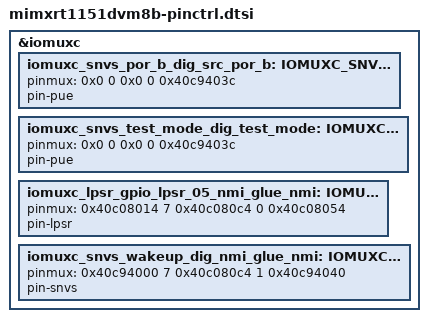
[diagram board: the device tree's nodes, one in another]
/*
 * Copyright 2026, NXP
 * SPDX-License-Identifier: Apache-2.0
 *
 * Note: File generated by gen_soc_headers.py
 * from configuration data for MIMXRT1151DVM8B
 */

/*
 * Delta-deduplicated by dedup_pinctrl.py:
 * based on mimxrt1176avm8a-pinctrl.dtsi with this part's differences applied
 * below (171 removed, 2 changed,
 * 2 added). Regenerate with dedup_pinctrl.py;
 * do not edit by hand.
 * target-hash: d0dcf505715381c8
 */

#include "mimxrt1176avm8a-pinctrl.dtsi"

/delete-node/ &iomuxc_gpio_ad_00_sim1_trxd;
/delete-node/ &iomuxc_gpio_ad_01_sim1_clk;
/delete-node/ &iomuxc_gpio_ad_02_sim1_rst_b;
/delete-node/ &iomuxc_gpio_ad_03_sim1_sven;
/delete-node/ &iomuxc_gpio_ad_04_sim1_pd;
/delete-node/ &iomuxc_gpio_ad_05_sim1_power_fail;
/delete-node/ &iomuxc_gpio_ad_06_enet_1588_event1_in;
/delete-node/ &iomuxc_gpio_ad_06_sim2_trxd;
/delete-node/ &iomuxc_gpio_ad_06_video_mux_csi_data15;
/delete-node/ &iomuxc_gpio_ad_07_enet_1588_event1_out;
/delete-node/ &iomuxc_gpio_ad_07_sim2_clk;
/delete-node/ &iomuxc_gpio_ad_07_video_mux_csi_data14;
/delete-node/ &iomuxc_gpio_ad_08_enet_1588_event2_in;
/delete-node/ &iomuxc_gpio_ad_08_sim2_rst_b;
/delete-node/ &iomuxc_gpio_ad_08_video_mux_csi_data13;
/delete-node/ &iomuxc_gpio_ad_09_enet_1588_event2_out;
/delete-node/ &iomuxc_gpio_ad_09_sim2_sven;
/delete-node/ &iomuxc_gpio_ad_09_video_mux_csi_data12;
/delete-node/ &iomuxc_gpio_ad_10_enet_1588_event3_in;
/delete-node/ &iomuxc_gpio_ad_10_sim2_pd;
/delete-node/ &iomuxc_gpio_ad_10_video_mux_csi_data11;
/delete-node/ &iomuxc_gpio_ad_11_enet_1588_event3_out;
/delete-node/ &iomuxc_gpio_ad_11_sim2_power_fail;
/delete-node/ &iomuxc_gpio_ad_11_video_mux_csi_data10;
/delete-node/ &iomuxc_gpio_ad_12_enet_tdata03;
/delete-node/ &iomuxc_gpio_ad_12_video_mux_csi_pixclk;
/delete-node/ &iomuxc_gpio_ad_13_enet_tdata02;
/delete-node/ &iomuxc_gpio_ad_13_video_mux_csi_mclk;
/delete-node/ &iomuxc_gpio_ad_14_enet_rx_clk;
/delete-node/ &iomuxc_gpio_ad_14_video_mux_csi_vsync;
/delete-node/ &iomuxc_gpio_ad_15_enet_tx_er;
/delete-node/ &iomuxc_gpio_ad_15_lpuart10_tx;
/delete-node/ &iomuxc_gpio_ad_15_video_mux_csi_hsync;
/delete-node/ &iomuxc_gpio_ad_16_enet_rdata03;
/delete-node/ &iomuxc_gpio_ad_16_lpuart10_rx;
/delete-node/ &iomuxc_gpio_ad_16_video_mux_csi_data09;
/delete-node/ &iomuxc_gpio_ad_17_enet_rdata02;
/delete-node/ &iomuxc_gpio_ad_17_video_mux_csi_data08;
/delete-node/ &iomuxc_gpio_ad_18_enet_crs;
/delete-node/ &iomuxc_gpio_ad_18_video_mux_csi_data07;
/delete-node/ &iomuxc_gpio_ad_19_enet_col;
/delete-node/ &iomuxc_gpio_ad_19_video_mux_csi_data06;
/delete-node/ &iomuxc_gpio_ad_20_video_mux_csi_data05;
/delete-node/ &iomuxc_gpio_ad_21_video_mux_csi_data04;
/delete-node/ &iomuxc_gpio_ad_22_video_mux_csi_data03;
/delete-node/ &iomuxc_gpio_ad_23_video_mux_csi_data02;
/delete-node/ &iomuxc_gpio_ad_24_enet_rx_en;
/delete-node/ &iomuxc_gpio_ad_24_video_mux_csi_data00;
/delete-node/ &iomuxc_gpio_ad_25_enet_rx_er;
/delete-node/ &iomuxc_gpio_ad_25_video_mux_csi_data01;
/delete-node/ &iomuxc_gpio_ad_26_enet_rdata00;
/delete-node/ &iomuxc_gpio_ad_27_enet_rdata01;
/delete-node/ &iomuxc_gpio_ad_28_enet_tx_en;
/delete-node/ &iomuxc_gpio_ad_29_enet_ref_clk;
/delete-node/ &iomuxc_gpio_ad_29_enet_tx_clk;
/delete-node/ &iomuxc_gpio_ad_30_enet_tdata00;
/delete-node/ &iomuxc_gpio_ad_31_enet_tdata01;
/delete-node/ &iomuxc_gpio_ad_32_enet_mdc;
/delete-node/ &iomuxc_gpio_ad_32_lpuart10_tx;
/delete-node/ &iomuxc_gpio_ad_33_enet_mdio;
/delete-node/ &iomuxc_gpio_ad_33_lpuart10_rx;
/delete-node/ &iomuxc_gpio_ad_34_enet_1588_event0_in;
/delete-node/ &iomuxc_gpio_ad_34_lpuart10_cts_b;
/delete-node/ &iomuxc_gpio_ad_35_enet_1588_event0_out;
/delete-node/ &iomuxc_gpio_ad_35_lpuart10_rts_b;
/delete-node/ &iomuxc_gpio_disp_b1_00_video_mux_lcdif_clk;
/delete-node/ &iomuxc_gpio_disp_b1_01_video_mux_lcdif_enable;
/delete-node/ &iomuxc_gpio_disp_b1_02_video_mux_lcdif_hsync;
/delete-node/ &iomuxc_gpio_disp_b1_03_video_mux_lcdif_vsync;
/delete-node/ &iomuxc_gpio_disp_b1_04_lpuart4_rx;
/delete-node/ &iomuxc_gpio_disp_b1_04_video_mux_lcdif_data00;
/delete-node/ &iomuxc_gpio_disp_b1_05_lpuart4_cts_b;
/delete-node/ &iomuxc_gpio_disp_b1_05_video_mux_lcdif_data01;
/delete-node/ &iomuxc_gpio_disp_b1_06_lpuart4_tx;
/delete-node/ &iomuxc_gpio_disp_b1_06_video_mux_lcdif_data02;
/delete-node/ &iomuxc_gpio_disp_b1_07_lpuart4_rts_b;
/delete-node/ &iomuxc_gpio_disp_b1_07_video_mux_lcdif_data03;
/delete-node/ &iomuxc_gpio_disp_b1_08_video_mux_lcdif_data04;
/delete-node/ &iomuxc_gpio_disp_b1_09_video_mux_lcdif_data05;
/delete-node/ &iomuxc_gpio_disp_b1_10_video_mux_lcdif_data06;
/delete-node/ &iomuxc_gpio_disp_b1_11_video_mux_lcdif_data07;
/delete-node/ &iomuxc_gpio_disp_b2_00_video_mux_lcdif_data08;
/delete-node/ &iomuxc_gpio_disp_b2_01_video_mux_lcdif_data09;
/delete-node/ &iomuxc_gpio_disp_b2_02_enet_tdata00;
/delete-node/ &iomuxc_gpio_disp_b2_02_video_mux_lcdif_data10;
/delete-node/ &iomuxc_gpio_disp_b2_03_enet_tdata01;
/delete-node/ &iomuxc_gpio_disp_b2_03_video_mux_lcdif_data11;
/delete-node/ &iomuxc_gpio_disp_b2_04_enet_tx_en;
/delete-node/ &iomuxc_gpio_disp_b2_04_video_mux_lcdif_data12;
/delete-node/ &iomuxc_gpio_disp_b2_05_enet_ref_clk;
/delete-node/ &iomuxc_gpio_disp_b2_05_enet_tx_clk;
/delete-node/ &iomuxc_gpio_disp_b2_05_video_mux_lcdif_data13;
/delete-node/ &iomuxc_gpio_disp_b2_06_enet_rdata00;
/delete-node/ &iomuxc_gpio_disp_b2_06_video_mux_lcdif_data14;
/delete-node/ &iomuxc_gpio_disp_b2_07_enet_rdata01;
/delete-node/ &iomuxc_gpio_disp_b2_07_video_mux_lcdif_data15;
/delete-node/ &iomuxc_gpio_disp_b2_08_enet_rx_en;
/delete-node/ &iomuxc_gpio_disp_b2_08_video_mux_lcdif_data16;
/delete-node/ &iomuxc_gpio_disp_b2_09_enet_rx_er;
/delete-node/ &iomuxc_gpio_disp_b2_09_video_mux_lcdif_data17;
/delete-node/ &iomuxc_gpio_disp_b2_10_sim2_trxd;
/delete-node/ &iomuxc_gpio_disp_b2_10_video_mux_lcdif_data18;
/delete-node/ &iomuxc_gpio_disp_b2_11_sim2_clk;
/delete-node/ &iomuxc_gpio_disp_b2_11_video_mux_lcdif_data19;
/delete-node/ &iomuxc_gpio_disp_b2_12_sim2_rst_b;
/delete-node/ &iomuxc_gpio_disp_b2_12_video_mux_lcdif_data20;
/delete-node/ &iomuxc_gpio_disp_b2_13_enet_ref_clk;
/delete-node/ &iomuxc_gpio_disp_b2_13_sim2_sven;
/delete-node/ &iomuxc_gpio_disp_b2_13_video_mux_lcdif_data21;
/delete-node/ &iomuxc_gpio_disp_b2_14_sim2_pd;
/delete-node/ &iomuxc_gpio_disp_b2_14_video_mux_lcdif_data22;
/delete-node/ &iomuxc_gpio_disp_b2_15_sim2_power_fail;
/delete-node/ &iomuxc_gpio_disp_b2_15_video_mux_lcdif_data23;
/delete-node/ &iomuxc_gpio_emc_b2_02_video_mux_csi_data23;
/delete-node/ &iomuxc_gpio_emc_b2_03_video_mux_csi_data22;
/delete-node/ &iomuxc_gpio_emc_b2_04_video_mux_csi_data21;
/delete-node/ &iomuxc_gpio_emc_b2_05_video_mux_csi_data20;
/delete-node/ &iomuxc_gpio_emc_b2_06_video_mux_csi_data19;
/delete-node/ &iomuxc_gpio_emc_b2_07_video_mux_csi_data18;
/delete-node/ &iomuxc_gpio_emc_b2_08_video_mux_csi_data17;
/delete-node/ &iomuxc_gpio_emc_b2_09_video_mux_csi_data16;
/delete-node/ &iomuxc_gpio_emc_b2_10_video_mux_csi_field;
/delete-node/ &iomuxc_gpio_emc_b2_11_sim1_trxd;
/delete-node/ &iomuxc_gpio_emc_b2_12_sim1_clk;
/delete-node/ &iomuxc_gpio_emc_b2_13_sim1_rst_b;
/delete-node/ &iomuxc_gpio_emc_b2_14_sim1_sven;
/delete-node/ &iomuxc_gpio_emc_b2_15_sim1_pd;
/delete-node/ &iomuxc_gpio_emc_b2_16_sim1_power_fail;
/delete-node/ &iomuxc_gpio_emc_b2_19_enet_mdc;
/delete-node/ &iomuxc_gpio_emc_b2_20_enet_mdio;
/delete-node/ &iomuxc_gpio_sd_b2_07_enet_tx_er;
/delete-node/ &iomuxc_lpsr_gpio_lpsr_00_can3_tx;
/delete-node/ &iomuxc_lpsr_gpio_lpsr_00_sai4_mclk;
/delete-node/ &iomuxc_lpsr_gpio_lpsr_01_can3_rx;
/delete-node/ &iomuxc_lpsr_gpio_lpsr_02_sai4_tx_data;
/delete-node/ &iomuxc_lpsr_gpio_lpsr_03_sai4_tx_sync;
/delete-node/ &iomuxc_lpsr_gpio_lpsr_04_lpi2c5_sda;
/delete-node/ &iomuxc_lpsr_gpio_lpsr_04_lpuart11_tx;
/delete-node/ &iomuxc_lpsr_gpio_lpsr_04_sai4_tx_bclk;
/delete-node/ &iomuxc_lpsr_gpio_lpsr_05_lpi2c5_scl;
/delete-node/ &iomuxc_lpsr_gpio_lpsr_05_lpuart11_rx;
/delete-node/ &iomuxc_lpsr_gpio_lpsr_05_sai4_mclk;
/delete-node/ &iomuxc_lpsr_gpio_lpsr_06_can3_tx;
/delete-node/ &iomuxc_lpsr_gpio_lpsr_06_lpspi6_pcs3;
/delete-node/ &iomuxc_lpsr_gpio_lpsr_06_sai4_rx_data;
/delete-node/ &iomuxc_lpsr_gpio_lpsr_07_can3_rx;
/delete-node/ &iomuxc_lpsr_gpio_lpsr_07_lpspi6_pcs2;
/delete-node/ &iomuxc_lpsr_gpio_lpsr_07_sai4_rx_bclk;
/delete-node/ &iomuxc_lpsr_gpio_lpsr_08_can3_tx;
/delete-node/ &iomuxc_lpsr_gpio_lpsr_08_lpi2c5_sda;
/delete-node/ &iomuxc_lpsr_gpio_lpsr_08_lpspi6_pcs1;
/delete-node/ &iomuxc_lpsr_gpio_lpsr_08_lpuart11_tx;
/delete-node/ &iomuxc_lpsr_gpio_lpsr_08_sai4_rx_sync;
/delete-node/ &iomuxc_lpsr_gpio_lpsr_09_can3_rx;
/delete-node/ &iomuxc_lpsr_gpio_lpsr_09_lpi2c5_scl;
/delete-node/ &iomuxc_lpsr_gpio_lpsr_09_lpspi6_pcs0;
/delete-node/ &iomuxc_lpsr_gpio_lpsr_09_lpuart11_rx;
/delete-node/ &iomuxc_lpsr_gpio_lpsr_09_sai4_tx_data;
/delete-node/ &iomuxc_lpsr_gpio_lpsr_10_lpi2c5_scls;
/delete-node/ &iomuxc_lpsr_gpio_lpsr_10_lpspi6_sck;
/delete-node/ &iomuxc_lpsr_gpio_lpsr_10_lpuart11_cts_b;
/delete-node/ &iomuxc_lpsr_gpio_lpsr_10_sai4_tx_sync;
/delete-node/ &iomuxc_lpsr_gpio_lpsr_11_lpi2c5_sdas;
/delete-node/ &iomuxc_lpsr_gpio_lpsr_11_lpspi6_sdo;
/delete-node/ &iomuxc_lpsr_gpio_lpsr_11_lpuart11_rts_b;
/delete-node/ &iomuxc_lpsr_gpio_lpsr_12_lpi2c5_hreq;
/delete-node/ &iomuxc_lpsr_gpio_lpsr_12_lpspi6_sdi;
/delete-node/ &iomuxc_lpsr_gpio_lpsr_12_sai4_tx_bclk;
/delete-node/ &iomuxc_lpsr_gpio_lpsr_13_sai4_rx_data;
/delete-node/ &iomuxc_lpsr_gpio_lpsr_14_sai4_rx_bclk;
/delete-node/ &iomuxc_lpsr_gpio_lpsr_15_sai4_rx_sync;
/delete-node/ &iomuxc_snvs_por_b_dig_src_por_b;
/delete-node/ &iomuxc_snvs_test_mode_dig_test_mode;

&iomuxc {
	/omit-if-no-ref/ iomuxc_snvs_por_b_dig_src_por_b: IOMUXC_SNVS_POR_B_DIG_SRC_POR_B {
		pinmux = <0x0 0 0x0 0 0x40c9403c>;
		pin-pue;
	};
	/omit-if-no-ref/ iomuxc_snvs_test_mode_dig_test_mode: IOMUXC_SNVS_TEST_MODE_DIG_TEST_MODE {
		pinmux = <0x0 0 0x0 0 0x40c9403c>;
		pin-pue;
	};
	/omit-if-no-ref/ iomuxc_lpsr_gpio_lpsr_05_nmi_glue_nmi: IOMUXC_LPSR_GPIO_LPSR_05_NMI_GLUE_NMI {
		pinmux = <0x40c08014 7 0x40c080c4 0 0x40c08054>;
		pin-lpsr;
	};
	/omit-if-no-ref/ iomuxc_snvs_wakeup_dig_nmi_glue_nmi: IOMUXC_SNVS_WAKEUP_DIG_NMI_GLUE_NMI {
		pinmux = <0x40c94000 7 0x40c080c4 1 0x40c94040>;
		pin-snvs;
	};
};
